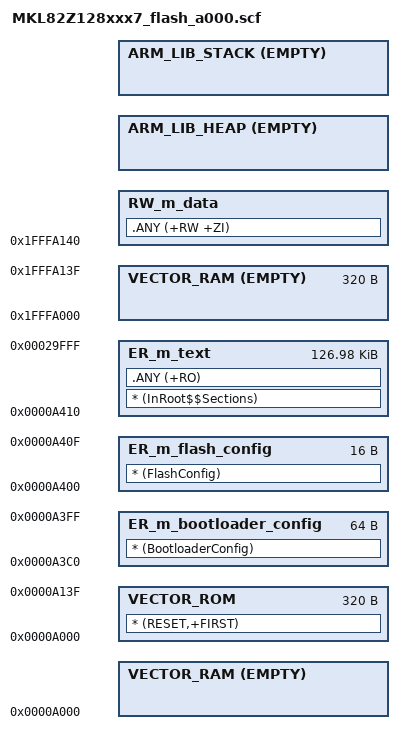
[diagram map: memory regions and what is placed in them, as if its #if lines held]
#! armcc -E
/*
** ###################################################################
**     Processors:          MKL82Z128VLH7
**                          MKL82Z128VLK7
**                          MKL82Z128VLL7
**                          MKL82Z128VMC7
**                          MKL82Z128VMP7
**
**     Compiler:            Keil ARM C/C++ Compiler
**     Reference manual:    KL82P121M72SF0RM, Rev.2 November 2015
**     Version:             rev. 1.5, 2015-09-24
**     Build:               b171205
**
**     Abstract:
**         Linker file for the Keil ARM C/C++ Compiler
**
**     Copyright (c) 2015 Freescale Semiconductor, Inc.
**     Copyright 2016-2018 NXP
**     All rights reserved.
**
**     SPDX-License-Identifier: BSD-3-Clause
**
**     http:                 www.nxp.com
**     mail:                 support@nxp.com
**
** ###################################################################
*/

#if (defined(__ram_vector_table__))
  #define __ram_vector_table_size__    0x00000140
#else
  #define __ram_vector_table_size__    0x00000000
#endif

#define m_interrupts_start             0x0000a000
#define m_interrupts_size              0x00000140

#define m_bootloader_config_start      0x0000a3C0
#define m_bootloader_config_size       0x00000040

#define m_flash_config_start           0x0000a400
#define m_flash_config_size            0x00000010

#define m_text_start                   0x0000a410
#define m_text_size                    0x0001FBF0

#define m_interrupts_ram_start         0x1FFFA000
#define m_interrupts_ram_size          __ram_vector_table_size__

#define m_data_start                   (m_interrupts_ram_start + m_interrupts_ram_size)
#define m_data_size                    (0x00018000 - m_interrupts_ram_size)

/* Sizes */
#if (defined(__stack_size__))
  #define Stack_Size                   __stack_size__
#else
  #define Stack_Size                   0x400
#endif

#if (defined(__heap_size__))
  #define Heap_Size                    __heap_size__
#else
  #define Heap_Size                    0x0
#endif

LR_m_text m_text_start m_text_size {   ; load region size_region
  ER_m_text m_text_start m_text_size { ; load address = execution address
    * (InRoot$$Sections)
    .ANY (+RO)
  }
  RW_m_data m_data_start m_data_size-Stack_Size-Heap_Size { ; RW data
    .ANY (+RW +ZI)
  }
  ARM_LIB_HEAP +0 EMPTY Heap_Size {    ; Heap region growing up
  }
  ARM_LIB_STACK m_data_start+m_data_size EMPTY -Stack_Size { ; Stack region growing down
  }
}

LR_m_interrupts m_interrupts_start m_interrupts_size {
#if (!defined(__ram_vector_table__))
  VECTOR_RAM m_interrupts_start EMPTY 0 {
  }
#endif
  VECTOR_ROM m_interrupts_start m_interrupts_size { ; load address = execution address
    * (RESET,+FIRST)
  }
}

LR_m_bootloader_config m_bootloader_config_start m_bootloader_config_size {
  ER_m_bootloader_config m_bootloader_config_start m_bootloader_config_size { ; load address = execution address
    * (BootloaderConfig)
  }
}

LR_m_flash_config m_flash_config_start m_flash_config_size {
  ER_m_flash_config m_flash_config_start m_flash_config_size { ; load address = execution address
    * (FlashConfig)
  }
}

#if (defined(__ram_vector_table__))
LR_m_interrupts_ram m_interrupts_ram_start m_interrupts_ram_size {
  VECTOR_RAM m_interrupts_ram_start EMPTY m_interrupts_ram_size {
  }
}
#endif

